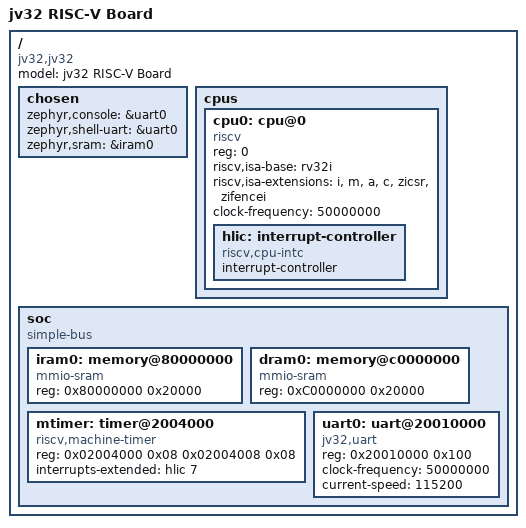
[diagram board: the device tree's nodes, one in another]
/*
 * Copyright (c) 2026 jv32 Project
 * SPDX-License-Identifier: Apache-2.0
 */

/dts-v1/;

#include <zephyr/dt-bindings/gpio/gpio.h>

/ {
    model = "jv32 RISC-V Board";
    compatible = "jv32,jv32";
    #address-cells = <1>;
    #size-cells = <1>;

    chosen {
        zephyr,console = &uart0;
        zephyr,shell-uart = &uart0;
        zephyr,sram = &iram0;
    };

    cpus {
        #address-cells = <1>;
        #size-cells = <0>;

        cpu0: cpu@0 {
            device_type = "cpu";
            compatible = "riscv";
            reg = <0>;
            riscv,isa-base = "rv32i";
            riscv,isa-extensions = "i", "m", "a", "c", "zicsr", "zifencei";
            clock-frequency = <50000000>;

            hlic: interrupt-controller {
                compatible = "riscv,cpu-intc";
                #interrupt-cells = <1>;
                interrupt-controller;
            };
        };
    };

    soc {
        #address-cells = <1>;
        #size-cells = <1>;
        compatible = "simple-bus";
        ranges;

        iram0: memory@80000000 {
            compatible = "mmio-sram";
            reg = <0x80000000 0x20000>;  /* 128KB IRAM (instruction TCM) */
        };

        dram0: memory@c0000000 {
            compatible = "mmio-sram";
            reg = <0xC0000000 0x20000>;  /* 128KB DRAM (data TCM) */
        };

        mtimer: timer@2004000 {
            compatible = "riscv,machine-timer";
            reg = <0x02004000 0x08    /* mtime: JV_CLIC_BASE + 0x4000 */
                   0x02004008 0x08>;  /* mtimecmp: JV_CLIC_BASE + 0x4008 */
            reg-names = "mtime", "mtimecmp";
            interrupts-extended = <&hlic 7>;
        };

        uart0: uart@20010000 {
            compatible = "jv32,uart";
            reg = <0x20010000 0x100>;
            clock-frequency = <50000000>;
            current-speed = <115200>;
            status = "okay";
        };
    };
};
